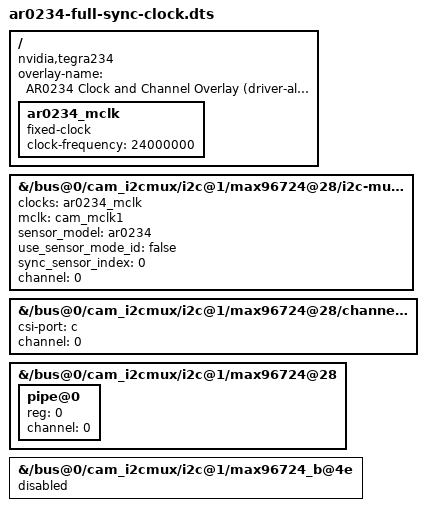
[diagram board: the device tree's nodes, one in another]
/dts-v1/;
/plugin/;

/ {
    overlay-name = "AR0234 Clock and Channel Overlay (driver-aligned)";
    compatible = "nvidia,tegra234",
                 "nvidia,p3768-0000+p3767-0005-super";

    /* 1) Fixed 24 MHz clock for AR0234 */
    fragment@0 {
        target-path = "/";
        __overlay__ {
            ar0234_mclk: ar0234_mclk {
                compatible = "fixed-clock";
                #clock-cells = <0>;
                clock-frequency = <24000000>;
            };
        };
    };

    /* 2) Sensor node (i2c@1) */
    fragment@1 {
        target-path = "/bus@0/cam_i2cmux/i2c@1/max96724@28/i2c-mux/i2c@0/camera@40";
        __overlay__ {
            status = "okay";

            clocks = <&ar0234_mclk>;
            clock-names = "cam_mclk1";
            mclk = "cam_mclk1";

            sensor_model = "ar0234";
            use_sensor_mode_id = "false";

            /* The driver expects these two exact integer properties */
            sync_sensor_index = <0>;
            channel = <0>;
        };
    };

    /* 3) Deserializer channel@0 */
    fragment@2 {
        target-path = "/bus@0/cam_i2cmux/i2c@1/max96724@28/channel@0";
        __overlay__ {
            status = "okay";
            csi-port = "c";
            channel = <0>;
        };
    };

    /* 4) Pipe linkage */
    fragment@3 {
        target-path = "/bus@0/cam_i2cmux/i2c@1/max96724@28";
        __overlay__ {
            pipe@0 {
                reg = <0>;
                status = "okay";
                channel = <0>;
            };
        };
    };

    /* 5) Disable stray deserializer */
    fragment@4 {
        target-path = "/bus@0/cam_i2cmux/i2c@1/max96724_b@4e";
        __overlay__ { status = "disabled"; };
    };
};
